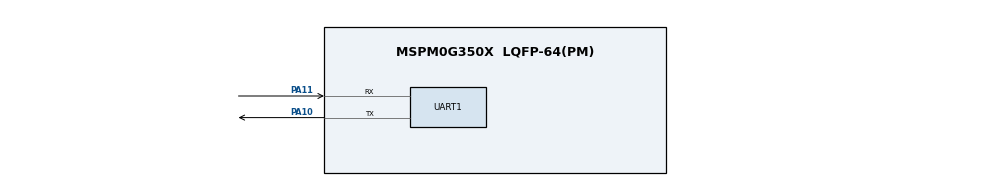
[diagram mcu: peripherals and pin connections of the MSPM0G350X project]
/**
 * @cliArgs --device "MSPM0G350X" --part "Default" --package "LQFP-64(PM)" --product "mspm0_sdk@2.09.00.00"
 * @versions {"tool":"1.26.0+4407"}
 */

/**
 * Import the modules used in this configuration.
 */
const GPIO   = scripting.addModule("/ti/driverlib/GPIO", {}, false);
const GPIO1  = GPIO.addInstance();
const SYSCTL = scripting.addModule("/ti/driverlib/SYSCTL");
const UART   = scripting.addModule("/ti/driverlib/UART", {}, false);
const UART1  = UART.addInstance();

/**
 * Write custom configuration values to the imported modules.
 */
GPIO1.$name                          = "GPIO_LED";
GPIO1.associatedPins[0].$name        = "LED_PIN_0";
GPIO1.associatedPins[0].assignedPort = "PORTB";
GPIO1.associatedPins[0].assignedPin  = "22";

const Board = scripting.addModule("/ti/driverlib/Board", {}, false);

SYSCTL.forceDefaultClkConfig = true;
SYSCTL.clockTreeEn           = true;

UART1.$name                                = "UART_0";
UART1.enableFIFO                           = true;
UART1.enableDMATX                          = false;
UART1.enabledDMARXTriggers                 = "DL_UART_DMA_INTERRUPT_RX";
UART1.targetBaudRate                       = 115200;
UART1.rxFifoThreshold                      = "DL_UART_RX_FIFO_LEVEL_ONE_ENTRY";
UART1.enabledInterrupts                    = ["DMA_DONE_RX"];
UART1.peripheral.$assign                   = "UART0";
UART1.peripheral.rxPin.$assign             = "PA11";
UART1.peripheral.txPin.$assign             = "PA10";
UART1.txPinConfig.$name                    = "ti_driverlib_gpio_GPIOPinGeneric0";
UART1.rxPinConfig.$name                    = "ti_driverlib_gpio_GPIOPinGeneric1";
UART1.DMA_CHANNEL_RX.$name                 = "DMA_CH0";
UART1.DMA_CHANNEL_RX.addressMode           = "f2b";
UART1.DMA_CHANNEL_RX.dstLength             = "BYTE";
UART1.DMA_CHANNEL_RX.srcLength             = "BYTE";
UART1.DMA_CHANNEL_RX.configureTransferSize = true;
UART1.DMA_CHANNEL_RX.transferMode          = "FULL_CH_REPEAT_SINGLE";
UART1.DMA_CHANNEL_RX.peripheral.$assign    = "DMA_CH0";

/**
 * Pinmux solution for unlocked pins/peripherals. This ensures that minor changes to the automatic solver in a future
 * version of the tool will not impact the pinmux you originally saw.  These lines can be completely deleted in order to
 * re-solve from scratch.
 */
GPIO1.associatedPins[0].pin.$suggestSolution = "PB22";
Board.peripheral.$suggestSolution            = "DEBUGSS";
Board.peripheral.swclkPin.$suggestSolution   = "PA20";
Board.peripheral.swdioPin.$suggestSolution   = "PA19";
